# RN831X_RN861X_MCU register map
File version: v0.0.1
CPU: RN831X_RN861X_MCU r1p0, little endian, MPU, no FPU
Registers are 32-bit, read-write, reset 0x0 unless marked. A register's access mark holds for its fields unless they carry their own. Offsets are from the block's base; [hi:lo] are bit positions; {n}, {i} and the like mark numbered series; 'fields as' and 'values as' point back to an identical list; <NAME> marks a mode.

## ADC0_CORE0 — ADC
Base 0x20094000
Same registers: ADC0_CORE1 0xA0094000
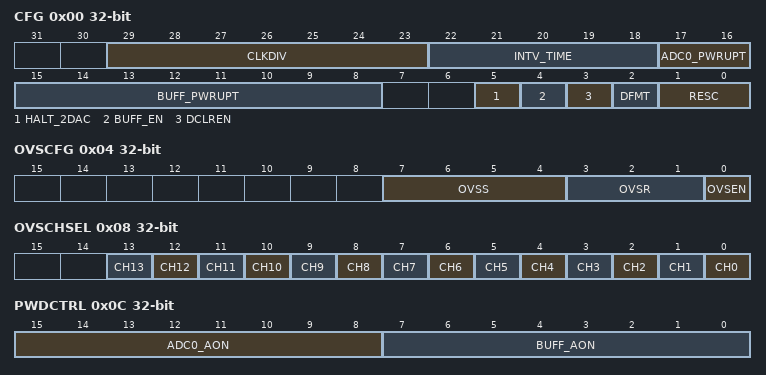
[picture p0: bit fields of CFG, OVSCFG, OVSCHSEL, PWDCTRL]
0x00 CFG access not given — Configuration Register
  [29:23] CLKDIV — ADC0 module working clock is bus clock divided by (CLKDIV+1)
  [22:18] INTV_TIME — Conversion interval wait cycles configuration bits.
  [17:16] ADC0_PWRUPT — power-up stabilization time bits (Time=ADC0_PWRUPT+32)(refer to reference manual for detail)
  [15:8] BUFF_PWRUPT — BUFFER power-up stabilization time bits (Time=BUFF_PWRUPT+32)(refer to reference manual for detail)
  [5] HALT_2DAC — DAC linkage configuration bit（ADC state select when DAC coverting）
    0=CONTINUE (ADC0 operates normally regardless of DAC status); 1=PAUSE (ADC0 pauses conversion when DAC is in conversion state)
  [4] BUFF_EN — channel input signal connects to ADC0 after amplification through BUFFER,function enable bit. (disable for signal connects directly to ADC)(Only can be configured when ADC0_STARTA=0 and ADC0_STARTB =0.)
  [3] DCLREN — Data register auto-clear enable bit
  [2] DFMT — Data format selection bits
    0=RA (Right-aligned data); 1=LA (Left-aligned data)
  [1:0] RESC — ADC resolution selection bits (Only can be configured when ADC0_STARTA=0 and ADC0_STARTB =0.)
    0=12BIT (select as 12-bit); 1=10BIT (select as 10-bit); 2=8BIT (select as 8-bit); 3=6BIT (select as 6-bit)
0x04 OVSCFG access not given — Oversampling Configuration Register
  [7:4] OVSS — Oversampling shift bits(Right Shift)
    0=SHLNUL (No shift); 1=SHL1 (Shift 1 bit); {v}=SHL{v} (Shift {v} bits) (v=2..8)
  [3:1] OVSR — Oversampling accumulation times
    0=ACC2 (Accumulate 2 times); 1=ACC4 (Accumulate 4 times); 2=ACC8 (Accumulate 8 times); 3=ACC16 (Accumulate 16 times); 4=ACC32 (Accumulate 32 times); 5=ACC64 (Accumulate 64 times); 6=ACC128 (Accumulate 128 times); 7=ACC256 (Accumulate 256 times)
  [0] OVSEN — Oversampling enable bit.(Only can be configured when ADC0_STARTA=0 and ADC0_STARTB =0.)
0x08 OVSCHSEL access not given — Oversampling Channel Configuration Register.Select whether each channel is oversampled.(Only can be configured when ADC0_STARTA=0 and ADC0_STARTB =0.)
  [all] fields
    0=DIS (disable channel oversampling); 1=EN (enable channel oversampling)
  [n] CH{n} (n=0..13) — CH{n} Oversampling enable bit.
0x0C PWDCTRL access not given — Power Switch Control Register
  [15:8] ADC0_AON — ADC0's analog circuit switch configuration bit
    165=ALWAYSON (ADC0 analog circuit always on); 0=DEMANDON (ADC0 analog circuit only turns on when working)
  [7:0] BUFF_AON — ADC0 BUFFER's analog circuit switch configuration bit
    172=ALWAYSON (BUFFER analog circuit always on); 0=DEMANDON (BUFFER analog circuit only turns on when working)
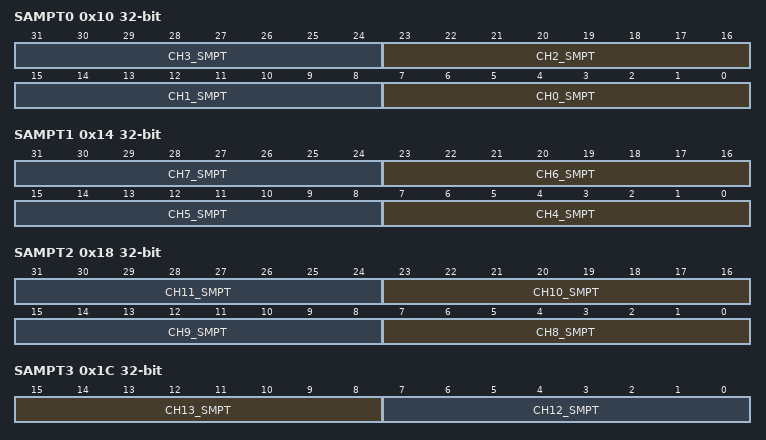
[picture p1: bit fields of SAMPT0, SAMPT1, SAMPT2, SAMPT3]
0x10 SAMPT0 access not given — Sampling Time Configuration Register for Input Channels 0~3
  [8n+7:8n] CH{n}_SMPT (n=0..3) — channel {n} sampling clock cycles configuration bits. Cycles = (CHN{n}_SMPT+1).
0x14 SAMPT1 access not given — Sampling Time Configuration Register for Input Channels 4~7
  [8n-25:8n-32] CH{n}_SMPT (n=4..7) — channel {n} sampling clock cycles configuration bits. Cycles = (CH{n}_SMPT+1).
0x18 SAMPT2 access not given — Sampling Time Configuration Register for Input Channels 8~11
  [8n-57:8n-64] CH{n}_SMPT (n=8..11) — channel {n} sampling clock cycles configuration bits. Cycles = (CH{n}_SMPT+1).
0x1C SAMPT3 access not given — Sampling Time Configuration Register for Input Channels 12~13
  [15:8] CH13_SMPT — channel 13 sampling clock cycles configuration bits. Cycles = (CH13_SMPT+1).
  [7:0] CH12_SMPT — channel 12 sampling clock cycles configuration bits. Cycles = (CH12_SMPT+1).
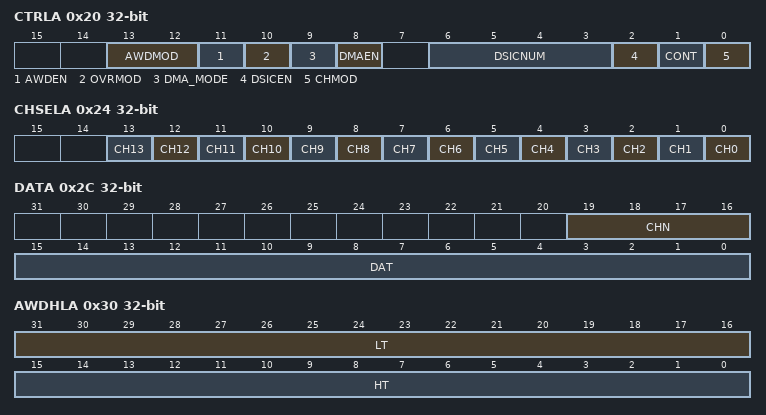
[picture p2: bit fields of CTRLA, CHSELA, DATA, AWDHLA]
0x20 CTRLA access not given — Sequence A Control Register
  [13:12] AWDMOD — Sequence A Analog Watchdog mode selection(Watchdog protection range,when data not in protection range AWD flag will be set)
    0=PHL (Protection range: AWD Low threshold< DATA < AWD High threshold); 1=PL (Protection range: AWD Low threshold< DATA); 2=PH (Protection range: DATA > AWD High threshold)
  [11] AWDEN — Sequence A Analog Watchdog enable bit
  [10] OVRMOD — Data overflow handling method seletion bit
    0=NUL (Do not recover data when overflow); 1=RECOVER (recover data when overflow)
  [9] DMA_MODE — DMA mode configuration bit
    0=ONCE (select DMA convert mode as convert once); 1=CONTIUE (select DMA convert mode as continuous convert)
  [8] DMAEN — Start DMA data transfer(only supports 16bit transfer)
  [6:3] DSICNUM — ADC0 discontinuous scan count configuration bits. count=(DSICNUM+1)
  [2] DSICEN — ADC0 discontinuous scan enable bit
  [1] CONT — Sequence A continuous conversion enable bit
    0=ONCE (ADC0 converts the specified channel(s) once); 1=CONTIUE (ADC0 continuously converts the specified channel(s) until software writes 0 to ADC0_STARTA)
  [0] CHMOD — Sequence A channel mode selection bit
    0=DATCH (Sequence AChannel configuration depend on ADC0_DATA_CHN); 1=CHSEL (Sequence AChannel configuration depend on ADC0_CHSELA)
0x24 CHSELA access not given — Sequence A Channel Selection Register
  [all] fields
    0=DIS (disable channel for Sequence A); 1=EN (enable channel for Sequence A)
  [n] CH{n} (n=0..13) — Channel {n} enable bit for Sequence A.
0x28 STARTA access not given — Sequence A Start Register
  [0] STARTA — Sequence A Start bit
0x2C DATA access not given — Sequence A Data Register
  [19:16] CHN — Sequence A current convert channel selection(only available when ADC0_CTRLA_CHMOD =0)
  [15:0] DAT ro — Sequence A current converting data
0x30 AWDHLA access not given — Sequence A Watchdog Threshold Register
  [31:16] LT — Watchdog low threshold
  [15:0] HT — Watchdog high threshold
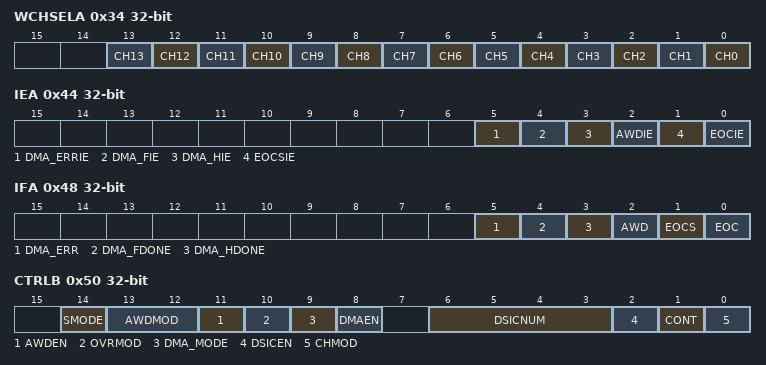
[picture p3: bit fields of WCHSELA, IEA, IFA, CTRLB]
0x34 WCHSELA access not given — Sequence A Watchdog Channel Selection Register
  [all] fields
    0=DIS (disable channel analog watch dog for Sequence A); 1=EN (enable channel analog watch dog for Sequence A)
  [n] CH{n} (n=0..13) — Channel {n} analog watch dog enable bit for Sequence A.
0x38 DMA_RBADRA access not given — Sequence A DMA Receive Base Address Register
  [17:0] DMA_RBADRA — Sequence A DMA Receive Base Address bits
0x3C DMA_RLENA access not given — Sequence A DMA Receive Length Register
  [17:0] DMA_RLENA — Sequence A DMA Receive Length bits
0x40 DMA_RADRA ro — Sequence A DMA Current Address Register
  [17:0] DMA_RADRA — Sequence A DMA Current Address bits
0x44 IEA — Sequence A Interrupt Enable Register
  [5] DMA_ERRIE — Sequence A DMA receive data overwrite interrupt enable bit
  [4] DMA_FIE — Sequence A DMA receive data full interrupt enable bit
  [3] DMA_HIE — Sequence A DMA receive data half-full interrupt enable bit
  [2] AWDIE — Sequence A watchdog event interrupt enable bit
  [1] EOCSIE — Sequence A End Of Conversion Sequence Interrupt Enable bit
  [0] EOCIE — Sequence A End Of Conversion Channel Interrupt Enable bit
0x48 IFA — Sequence A Interrupt Flag Register
  [5] DMA_ERR write-1-clears — Sequence A DMA receive data overwrite flag
  [4] DMA_FDONE write-1-clears — Sequence A DMA receive data full flag
  [3] DMA_HDONE write-1-clears — Sequence A DMA receive data half-full flag
  [2] AWD write-1-clears — Sequence A watchdog event flag
  [1] EOCS write-1-clears — Sequence A End Of Conversion Sequence Flag
  [0] EOC write-1-clears — Sequence A End Of Conversion Channel Flag
0x50 CTRLB access not given — Sequence B Control Register
  [14] SMODE — Processing method selection when sequence B is preempted
    0=STOP (Force abort conversion and switch to sequence A); 1=WAIT (Wait for current conversion to complete before switching to sequence A)
  [13:12] AWDMOD — Sequence B Analog Watchdog mode selection(Watchdog protection range,when data not in protection range AWD flag will be set)
    values as CTRLA.AWDMOD
  [11] AWDEN — Sequence B Analog Watchdog enable bit
  [10] OVRMOD — Data overflow handling method seletion bit
    values as CTRLA.OVRMOD
  [9] DMA_MODE — DMA mode configuration bit
    values as CTRLA.DMA_MODE
  [8] DMAEN — Start DMA data transfer(only supports 16bit transfer)
  [6:3] DSICNUM — ADC0 discontinuous scan count configuration bits. count=(DSICNUM+1)
  [2] DSICEN — ADC0 discontinuous scan enable bit
  [1] CONT — Sequence B continuous conversion enable bit
    values as CTRLA.CONT
  [0] CHMOD — Sequence B channel mode selection bit
    0=DATCH (Sequence B Channel configuration depend on ADC0_DATB_CHN); 1=CHSEL (Sequence B Channel configuration depend on ADC0_CHSELB)
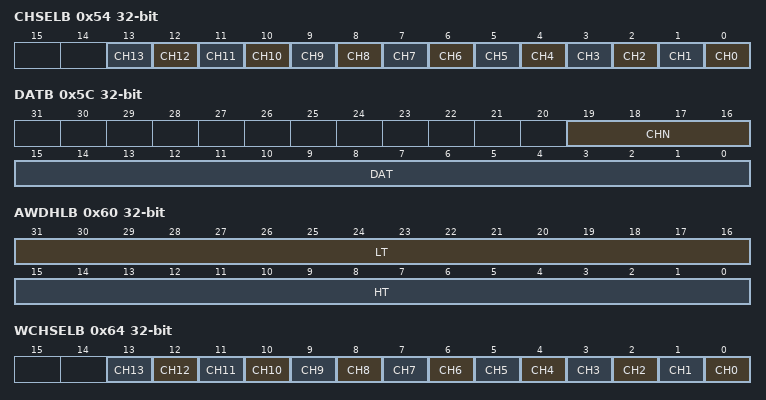
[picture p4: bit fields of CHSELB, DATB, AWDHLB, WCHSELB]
0x54 CHSELB access not given — Sequence B Channel Selection Register
  [all] fields
    0=DIS (disable channel for Sequence B); 1=EN (enable channel for Sequence B)
  [n] CH{n} (n=0..13) — Channel {n} enable bit for Sequence B.
0x58 STARTB access not given — Sequence B Start Register
  [0] STARTB — Sequence B Start bit
0x5C DATB access not given — Sequence B Data Register
  [19:16] CHN — Sequence B current convert channel selection(only available when ADC0_CTRLB_CHMOD =0)
  [15:0] DAT ro — Sequence B current converting data
0x60 AWDHLB access not given — Sequence B Watchdog Threshold Register
  fields as AWDHLA
0x64 WCHSELB access not given — Sequence B Watchdog Channel Selection Register
  [all] fields
    0=DIS (disable channel analog watch dog for Sequence B); 1=EN (enable channel analog watch dog for Sequence B)
  [n] CH{n} (n=0..13) — Channel {n} analog watch dog enable bit for Sequence B.
0x68 DMA_RBADRB access not given — Sequence B DMA Receive Base Address Register
  [17:0] DMA_RBADRB — Sequence B DMA Receive Base Address bits
0x6C DMA_RLENB access not given — Sequence B DMA Receive Length Register
  [17:0] DMA_RLENB — Sequence B DMA Receive Length bits
0x70 DMA_RADRB ro — Sequence B DMA Current Address Register
  [17:0] DMA_RADRB — Sequence B DMA Current Address bits
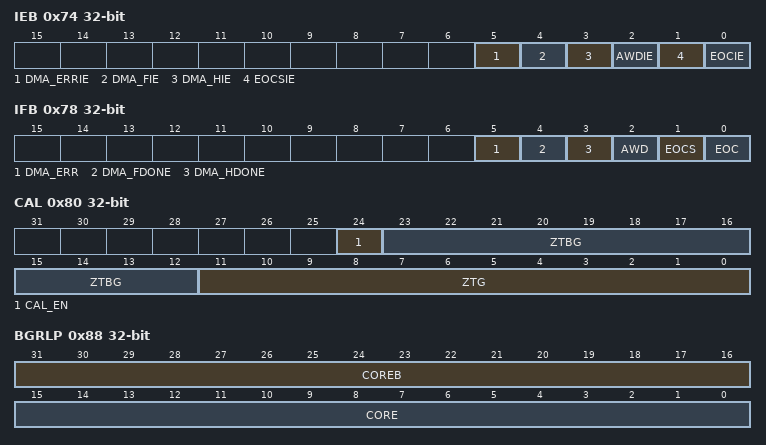
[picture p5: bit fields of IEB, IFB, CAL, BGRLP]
0x74 IEB — Sequence B Interrupt Enable Register
  [5] DMA_ERRIE — Sequence B DMA receive data overwrite interrupt enable bit
  [4] DMA_FIE — Sequence B DMA receive data full interrupt enable bit
  [3] DMA_HIE — Sequence B DMA receive data half-full interrupt enable bit
  [2] AWDIE — Sequence B watchdog event interrupt enable bit
  [1] EOCSIE — Sequence B End Of Conversion Sequence Interrupt Enable bit
  [0] EOCIE — Sequence B End Of Conversion Channel Interrupt Enable bit
0x78 IFB — Sequence B Interrupt Flag Register
  [5] DMA_ERR write-1-clears — Sequence B DMA receive data overwrite flag
  [4] DMA_FDONE write-1-clears — Sequence B DMA receive data full flag
  [3] DMA_HDONE write-1-clears — Sequence B DMA receive data half-full flag
  [2] AWD write-1-clears — Sequence B watchdog event flag
  [1] EOCS write-1-clears — Sequence B End Of Conversion Sequence Flag
  [0] EOC write-1-clears — Sequence B End Of Conversion Channel Flag
0x80 CAL access not given — Calibration config Register
  [24] CAL_EN — Hardware calibration enable bit(Only can be configured when ADC0_STARTA=0 and ADC0_STARTB =0.)
  [23:12] ZTBG — ZEROT calabration value for the condition that BUFFER is enabled (Only can be configured when ADC0_STARTA=0 and ADC0_STARTB =0.)
  [11:0] ZTG — ZEROT calabration value for the condition that BUFFER is disabled (Only can be configured when ADC0_STARTA=0 and ADC0_STARTB =0.)
0x84 DOS access not given — Digital Offset Code Value Configuration Register
  [11:0] DOS — (Two's complement signed value) Digital Offset Code Value Configuration bits
0x88 BGRLP access not given — BGRLP Channel Ideal Code Value Register
  [31:16] COREB — accumulated code theroy value, when buffer enabled
  [15:0] CORE — accumulated code theroy value, when buffer disabled
0x94 DCONV access not given — Dummy Conversion Configuration Register
  [1:0] DCONV — Configuration of dummy conversion count after power-on.
